# STM32G0B1 register map
File version: 1.5
CPU: CM0 r0p1, little endian, MPU, no FPU, 4 interrupt priority bits
Registers are 32-bit, read-write, reset 0x0 unless marked. A register's access mark holds for its fields unless they carry their own. Offsets are from the block's base; [hi:lo] are bit positions.

## HDMI_CEC
Base 0x40007800
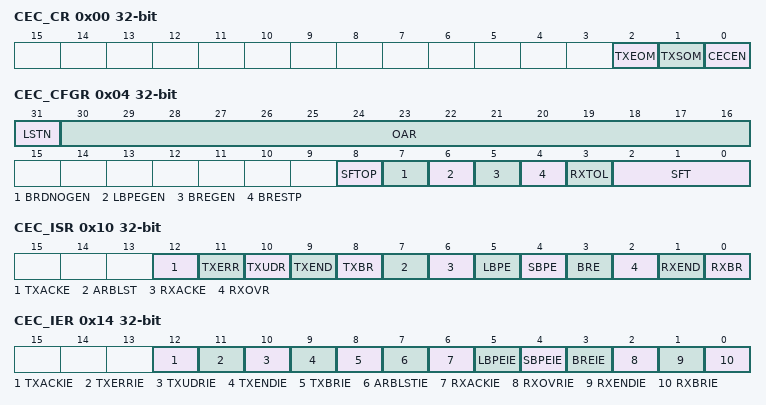
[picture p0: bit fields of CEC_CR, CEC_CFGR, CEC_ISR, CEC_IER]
0x00 CEC_CR — CEC control register
  [2] TXEOM — Tx end of message The TXEOM bit is set by software to command transmission of the last byte of a CEC message. TXEOM is cleared by hardware at the same time and under the same conditions as for TXSOM. Note: TXEOM must be set when CECEN = 1. TXEOM must be set before writing transmission data to TXDR. If TXEOM is set when TXSOM = 0, transmitted message consists of 1 byte (HEADER) only (PING message).
    0=TXDR data byte is transmitted with EOM = 0; 1=TXDR data byte is transmitted with EOM = 1
  [1] TXSOM — Tx start of message TXSOM is set by software to command transmission of the first byte of a CEC message. If the CEC message consists of only one byte, TXEOM must be set before of TXSOM. Start-bit is effectively started on the CEC line after SFT is counted. If TXSOM is set while a message reception is ongoing, transmission starts after the end of reception. TXSOM is cleared by hardware after the last byte of the message is sent with a positive acknowledge (TXEND = 1), in case of transmission underrun (TXUDR = 1), negative acknowledge (TXACKE = 1), and transmission error (TXERR = 1). It is also cleared by CECEN = 0. It is not cleared and transmission is automatically retried in case of arbitration lost (ARBLST = 1). TXSOM can be also used as a status bit informing application whether any transmission request is pending or under execution. The application can abort a transmission request at any time by clearing the CECEN bit. Note: TXSOM must be set when CECEN = 1. TXSOM must be set when transmission data is available into TXDR. HEADER first four bits containing own peripheral address are taken from TXDR[7:4], not from CEC_CFGR.OAR that is used only for reception.
    0=No CEC transmission is on-going; 1=CEC transmission command
  [0] CECEN — CEC enable The CECEN bit is set and cleared by software. CECEN = 1 starts message reception and enables the TXSOM control. CECEN = 0 disables the CEC peripheral, clears all bits of CEC_CR register and aborts any on-going reception or transmission.
    0=CEC peripheral is off; 1=CEC peripheral is on
0x04 CEC_CFGR — This register is used to configure the HDMI-CEC controller. It is mandatory to write CEC_CFGR only when CECEN=0.
  [31] LSTN — Listen mode LSTN bit is set and cleared by software.
    0=CEC peripheral receives only message addressed to its own address (OAR). Messages addressed to different destination are ignored. Broadcast messages are always received.; 1=CEC peripheral receives messages addressed to its own address (OAR) with positive acknowledge. Messages addressed to different destination are received, but without interfering with the CEC bus: no acknowledge sent.
  [30:16] OAR — Own addresses configuration The OAR bits are set by software to select which destination logical addresses has to be considered in receive mode. Each bit, when set, enables the CEC logical address identified by the given bit position. At the end of HEADER reception, the received destination address is compared with the enabled addresses. In case of matching address, the incoming message is acknowledged and received. In case of non-matching address, the incoming message is received only in listen mode (LSTN = 1), but without acknowledge sent. Broadcast messages are always received. Example: OAR = 0b000 0000 0010 0001 means that CEC acknowledges addresses 0x0 and 0x5. Consequently, each message directed to one of these addresses is received.
  [8] SFTOP — SFT option bit The SFTOPT bit is set and cleared by software.
    0=SFT timer starts when TXSOM is set by software; 1=SFT timer starts automatically at the end of message transmission/reception
  [7] BRDNOGEN — Avoid error-bit generation in broadcast The BRDNOGEN bit is set and cleared by software. error-bit on the CEC line. LBPE detection with LBPEGEN = 0 on a broadcast message generates an error-bit on the CEC line.
    0=BRE detection with BRESTP = 1 and BREGEN = 0 on a broadcast message generates an; 1=Error-bit is not generated in the same condition as above. An error-bit is not generated even in case of an SBPE detection in a broadcast message if listen mode is set.
  [6] LBPEGEN — Generate error-bit on long bit period error The LBPEGEN bit is set and cleared by software. Note: If BRDNOGEN = 0, an error-bit is generated upon LBPE detection in broadcast even if LBPEGEN = 0.
    0=LBPE detection does not generate an error-bit on the CEC line; 1=LBPE detection generates an error-bit on the CEC line
  [5] BREGEN — Generate error-bit on bit rising error The BREGEN bit is set and cleared by software. Note: If BRDNOGEN = 0, an error-bit is generated upon BRE detection with BRESTP = 1 in broadcast even if BREGEN = 0.
    0=BRE detection does not generate an error-bit on the CEC line; 1=BRE detection generates an error-bit on the CEC line (if BRESTP is set)
  [4] BRESTP — Rx-stop on bit rising error The BRESTP bit is set and cleared by software.
    0=BRE detection does not stop reception of the CEC message. Data bit is sampled at 1.05 ms.; 1=BRE detection stops message reception
  [3] RXTOL — Rx-tolerance The RXTOL bit is set and cleared by software. Start-bit, +/- 200 us rise, +/- 200 us fall Data-bit: +/- 200 us rise. +/- 350 us fall Start-bit: +/- 400 us rise, +/- 400 us fall Data-bit: +/-300 us rise, +/- 500 us fall
    0=Standard tolerance margin:; 1=Extended tolerance
  [2:0] SFT — Signal free time SFT bits are set by software. In the SFT = 0x0 configuration, the number of nominal data bit periods waited before transmission is ruled by hardware according to the transmission history. In all the other configurations the SFT number is determined by software. 0x0 2.5 data-bit periods if CEC is the last bus initiator with unsuccessful transmission (ARBLST = 1, TXERR = 1, TXUDR = 1 or TXACKE = 1) 4 data-bit periods if CEC is the new bus initiator 6 data-bit periods if CEC is the last bus initiator with successful transmission (TXEOM = 1)
    1=0.5 nominal data bit periods; 2=1.5 nominal data bit periods; 3=2.5 nominal data bit periods; 4=3.5 nominal data bit periods; 5=4.5 nominal data bit periods; 6=5.5 nominal data bit periods; 7=6.5 nominal data bit periods
0x08 CEC_TXDR wo — CEC Tx data register
  [7:0] TXD — Tx Data register. TXD is a write-only register containing the data byte to be transmitted. Note: TXD must be written when TXSTART=1
0x0C CEC_RXDR ro — CEC Rx Data Register
  [7:0] RXD — Rx Data register. RXD is read-only and contains the last data byte which has been received from the CEC line.
0x10 CEC_ISR — CEC Interrupt and Status Register
  [12] TXACKE — Tx-Missing Acknowledge Error In transmission mode, TXACKE is set by hardware to inform application that no acknowledge was received. In case of broadcast transmission, TXACKE informs application that a negative acknowledge was received. TXACKE aborts message transmission and clears TXSOM and TXEOM controls. TXACKE is cleared by software write at 1.
  [11] TXERR — Tx-Error In transmission mode, TXERR is set by hardware if the CEC initiator detects low impedance on the CEC line while it is released. TXERR aborts message transmission and clears TXSOM and TXEOM controls. TXERR is cleared by software write at 1.
  [10] TXUDR — Tx-Buffer Underrun In transmission mode, TXUDR is set by hardware if application was not in time to load TXDR before of next byte transmission. TXUDR aborts message transmission and clears TXSOM and TXEOM control bits. TXUDR is cleared by software write at 1
  [9] TXEND — End of Transmission TXEND is set by hardware to inform application that the last byte of the CEC message has been successfully transmitted. TXEND clears the TXSOM and TXEOM control bits. TXEND is cleared by software write at 1.
  [8] TXBR — Tx-Byte Request TXBR is set by hardware to inform application that the next transmission data has to be written to TXDR. TXBR is set when the 4th bit of currently transmitted byte is sent. Application must write the next byte to TXDR within 6 nominal data-bit periods before transmission underrun error occurs (TXUDR). TXBR is cleared by software write at 1.
  [7] ARBLST — Arbitration Lost ARBLST is set by hardware to inform application that CEC device is switching to reception due to arbitration lost event following the TXSOM command. ARBLST can be due either to a contending CEC device starting earlier or starting at the same time but with higher HEADER priority. After ARBLST assertion TXSOM bit keeps pending for next transmission attempt. ARBLST is cleared by software write at 1.
  [6] RXACKE — Rx-Missing Acknowledge In receive mode, RXACKE is set by hardware to inform application that no acknowledge was seen on the CEC line. RXACKE applies only for broadcast messages and in listen mode also for not directly addressed messages (destination address not enabled in OAR). RXACKE aborts message reception. RXACKE is cleared by software write at 1.
  [5] LBPE — Rx-Long Bit Period Error LBPE is set by hardware in case a Data-Bit waveform is detected with Long Bit Period Error. LBPE is set at the end of the maximum bit-extension tolerance allowed by RXTOL, in case falling edge is still longing. LBPE always stops reception of the CEC message. LBPE generates an Error-Bit on the CEC line if LBPEGEN=1. In case of broadcast, Error-Bit is generated even in case of LBPEGEN=0. LBPE is cleared by software write at 1.
  [4] SBPE — Rx-Short Bit Period Error SBPE is set by hardware in case a Data-Bit waveform is detected with Short Bit Period Error. SBPE is set at the time the anticipated falling edge occurs. SBPE generates an Error-Bit on the CEC line. SBPE is cleared by software write at 1.
  [3] BRE — Rx-Bit Rising Error BRE is set by hardware in case a Data-Bit waveform is detected with Bit Rising Error. BRE is set either at the time the misplaced rising edge occurs, or at the end of the maximum BRE tolerance allowed by RXTOL, in case rising edge is still longing. BRE stops message reception if BRESTP=1. BRE generates an Error-Bit on the CEC line if BREGEN=1. BRE is cleared by software write at 1.
  [2] RXOVR — Rx-Overrun RXOVR is set by hardware if RXBR is not yet cleared at the time a new byte is received on the CEC line and stored into RXD. RXOVR assertion stops message reception so that no acknowledge is sent. In case of broadcast, a negative acknowledge is sent. RXOVR is cleared by software write at 1.
  [1] RXEND — End Of Reception RXEND is set by hardware to inform application that the last byte of a CEC message is received from the CEC line and stored into the RXD buffer. RXEND is set at the same time of RXBR. RXEND is cleared by software write at 1.
  [0] RXBR — Rx-Byte Received The RXBR bit is set by hardware to inform application that a new byte has been received from the CEC line and stored into the RXD buffer. RXBR is cleared by software write at 1.
0x14 CEC_IER — CEC interrupt enable register
  [12] TXACKIE — Tx-missing acknowledge error interrupt enable The TXACKEIE bit is set and cleared by software.
    0=TXACKE interrupt disabled; 1=TXACKE interrupt enabled
  [11] TXERRIE — Tx-error interrupt enable The TXERRIE bit is set and cleared by software.
    0=TXERR interrupt disabled; 1=TXERR interrupt enabled
  [10] TXUDRIE — Tx-underrun interrupt enable The TXUDRIE bit is set and cleared by software.
    0=TXUDR interrupt disabled; 1=TXUDR interrupt enabled
  [9] TXENDIE — Tx-end of message interrupt enable The TXENDIE bit is set and cleared by software.
    0=TXEND interrupt disabled; 1=TXEND interrupt enabled
  [8] TXBRIE — Tx-byte request interrupt enable The TXBRIE bit is set and cleared by software.
    0=TXBR interrupt disabled; 1=TXBR interrupt enabled
  [7] ARBLSTIE — Arbitration lost interrupt enable The ARBLSTIE bit is set and cleared by software.
    0=ARBLST interrupt disabled; 1=ARBLST interrupt enabled
  [6] RXACKIE — Rx-missing acknowledge error interrupt enable The RXACKIE bit is set and cleared by software.
    0=RXACKE interrupt disabled; 1=RXACKE interrupt enabled
  [5] LBPEIE — Long bit period error interrupt enable The LBPEIE bit is set and cleared by software.
    0=LBPE interrupt disabled; 1=LBPE interrupt enabled
  [4] SBPEIE — Short bit period error interrupt enable The SBPEIE bit is set and cleared by software.
    0=SBPE interrupt disabled; 1=SBPE interrupt enabled
  [3] BREIE — Bit rising error interrupt enable The BREIE bit is set and cleared by software.
    0=BRE interrupt disabled; 1=BRE interrupt enabled
  [2] RXOVRIE — Rx-buffer overrun interrupt enable The RXOVRIE bit is set and cleared by software.
    0=RXOVR interrupt disabled; 1=RXOVR interrupt enabled
  [1] RXENDIE — End of reception interrupt enable The RXENDIE bit is set and cleared by software.
    0=RXEND interrupt disabled; 1=RXEND interrupt enabled
  [0] RXBRIE — Rx-byte received interrupt enable The RXBRIE bit is set and cleared by software.
    0=RXBR interrupt disabled; 1=RXBR interrupt enabled
